AUTOSAR XML (schema 4-3-0)
standard types defined: UInt16, UInt32, UInt8, uint16, uint32, uint8
package /ARRoot/If
  11 x nv data interface:
    BsConst_BsConst_Illumination_ReservedByte
      nv-datas:
        data Value: type=Arr_u8_28
    BsConst_Compensation_Line_Shift_b
      nv-datas:
        data Value: type=UInt32
    BsConst_Compensation_Line_Slope_m
      nv-datas:
        data Value: type=UInt32
    BsConst_Derating_Backlight_Disable
      nv-datas:
        data Value: type=UInt8
    BsConst_Display_Illum_Max_Level
      nv-datas:
        data Value: type=UInt16
    BsConst_Lookup_Curve_HotSpot_Coef_X
      nv-datas:
        data Value: type=Arr_u16_7
    BsConst_Lookup_Curve_HotSpot_Coef_Y
      nv-datas:
        data Value: type=Arr_u16_7
    BsConst_PCB_Temperature_Sensor_Conv
      nv-datas:
        data Value: type=T_NV_Temperature_Conversion
    BsConst_PWM_boost_bypass_duty
      nv-datas:
        data Value: type=UInt8
    BsConst_Temp_Threshold_Hysteresis_Derating
      nv-datas:
        data Value: type=UInt8
    BsConst_Temperature_Sensor_Conv
      nv-datas:
        data Value: type=T_NV_Temperature_Conversion
package /E40_Platform_System_SystemPackage/Components
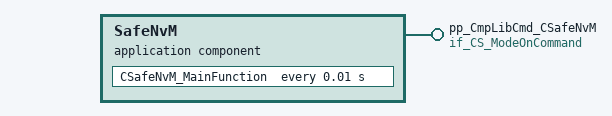
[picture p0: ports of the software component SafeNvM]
  application sw component type SafeNvM
    provide port pp_CmpLibCmd_CSafeNvM: server-com-spec{operation=Impl_OnCommand, queue-length=1}, provided-interface=if_CS_ModeOnCommand
    11 x provide/require port:
      BsConst_BsConst_Illumination_ReservedByte: nv-provide-com-spec=BsConst_BsConst_Illumination_ReservedByte/Value, nv-require-com-spec=BsConst_BsConst_Illumination_ReservedByte/Value, provided-required-interface=BsConst_BsConst_Illumination_ReservedByte
      BsConst_Compensation_Line_Shift_b: nv-provide-com-spec=BsConst_Compensation_Line_Shift_b/Value, nv-require-com-spec=BsConst_Compensation_Line_Shift_b/Value, provided-required-interface=BsConst_Compensation_Line_Shift_b
      BsConst_Compensation_Line_Slope_m: nv-provide-com-spec=BsConst_Compensation_Line_Slope_m/Value, nv-require-com-spec=BsConst_Compensation_Line_Slope_m/Value, provided-required-interface=BsConst_Compensation_Line_Slope_m
      BsConst_Derating_Backlight_Disable: nv-provide-com-spec=BsConst_Derating_Backlight_Disable/Value, nv-require-com-spec=BsConst_Derating_Backlight_Disable/Value, provided-required-interface=BsConst_Derating_Backlight_Disable
      BsConst_Display_Illum_Max_Level_Safe: nv-provide-com-spec=BsConst_Display_Illum_Max_Level/Value, nv-require-com-spec=BsConst_Display_Illum_Max_Level/Value, provided-required-interface=BsConst_Display_Illum_Max_Level
      BsConst_Lookup_Curve_HotSpot_Coef_X: nv-provide-com-spec=BsConst_Lookup_Curve_HotSpot_Coef_X/Value, nv-require-com-spec=BsConst_Lookup_Curve_HotSpot_Coef_X/Value, provided-required-interface=BsConst_Lookup_Curve_HotSpot_Coef_X
      BsConst_Lookup_Curve_HotSpot_Coef_Y: nv-provide-com-spec=BsConst_Lookup_Curve_HotSpot_Coef_Y/Value, nv-require-com-spec=BsConst_Lookup_Curve_HotSpot_Coef_Y/Value, provided-required-interface=BsConst_Lookup_Curve_HotSpot_Coef_Y
      BsConst_PCB_Temperature_Sensor_Conv: nv-provide-com-spec=BsConst_PCB_Temperature_Sensor_Conv/Value, nv-require-com-spec=BsConst_PCB_Temperature_Sensor_Conv/Value, provided-required-interface=BsConst_PCB_Temperature_Sensor_Conv
      BsConst_PWM_boost_bypass_duty: nv-provide-com-spec=BsConst_PWM_boost_bypass_duty/Value, nv-require-com-spec=BsConst_PWM_boost_bypass_duty/Value, provided-required-interface=BsConst_PWM_boost_bypass_duty
      BsConst_Temp_Threshold_Hysteresis_Derating: nv-provide-com-spec=BsConst_Temp_Threshold_Hysteresis_Derating/Value, nv-require-com-spec=BsConst_Temp_Threshold_Hysteresis_Derating/Value, provided-required-interface=BsConst_Temp_Threshold_Hysteresis_Derating
      BsConst_Temperature_Sensor_Conv: nv-provide-com-spec=BsConst_Temperature_Sensor_Conv/Value, nv-require-com-spec=BsConst_Temperature_Sensor_Conv/Value, provided-required-interface=BsConst_Temperature_Sensor_Conv
    behavior IB_SafeNvM: port-api-option{enable-take-address=false, error-handling=NO-TRANSFORMER-ERROR-HANDLING, indirect-api=false, port=pp_CmpLibCmd_CSafeNvM}
      operation invoked event OIE_pp_CmpLibCmd_CSafeNvM_CSafeNvM_Impl_OnCommandTrigByImpl_OnCommand: start-on-event=CSafeNvM_Impl_OnCommand, operation=pp_CmpLibCmd_CSafeNvM.Impl_OnCommand
      timing event TECSafeNvM_MainFunction: start-on-event=CSafeNvM_MainFunction, period=0.01
      11 x data received event:
        DRT_OnDre_Compensation_Line_Shift_b_BsConst_Compensation_Line_Shift_b_Value: start-on-event=OnDre_Compensation_Line_Shift_b, data=BsConst_Compensation_Line_Shift_b.Value
        DRT_OnDre_Compensation_Line_Slope_m_BsConst_Compensation_Line_Slope_m_Value: start-on-event=OnDre_Compensation_Line_Slope_m, data=BsConst_Compensation_Line_Slope_m.Value
        DRT_OnDre_Derating_Backlight_Disable_BsConst_Derating_Backlight_Disable_Value: start-on-event=OnDre_Derating_Backlight_Disable, data=BsConst_Derating_Backlight_Disable.Value
        DRT_OnDre_Display_Illum_Max_Level_Safe_BsConst_Display_Illum_Max_Level_Safe_Value: start-on-event=OnDre_Display_Illum_Max_Level_Safe, data=BsConst_Display_Illum_Max_Level_Safe.Value
        DRT_OnDre_Illumination_ReservedByte_BsConst_BsConst_Illumination_ReservedByte_Value: start-on-event=OnDre_Illumination_ReservedByte, data=BsConst_BsConst_Illumination_ReservedByte.Value
        DRT_OnDre_Lookup_Curve_HotSpot_Coef_X_BsConst_Lookup_Curve_HotSpot_Coef_X_Value: start-on-event=OnDre_Lookup_Curve_HotSpot_Coef_X, data=BsConst_Lookup_Curve_HotSpot_Coef_X.Value
        DRT_OnDre_Lookup_Curve_HotSpot_Coef_Y_BsConst_Lookup_Curve_HotSpot_Coef_Y_Value: start-on-event=OnDre_Lookup_Curve_HotSpot_Coef_Y, data=BsConst_Lookup_Curve_HotSpot_Coef_Y.Value
        DRT_OnDre_PCB_Temperature_Sensor_Conv_BsConst_PCB_Temperature_Sensor_Conv_Value: start-on-event=OnDre_PCB_Temperature_Sensor_Conv, data=BsConst_PCB_Temperature_Sensor_Conv.Value
        DRT_OnDre_PWM_boost_bypass_duty_BsConst_PWM_boost_bypass_duty_Value: start-on-event=OnDre_PWM_boost_bypass_duty, data=BsConst_PWM_boost_bypass_duty.Value
        DRT_OnDre_Temp_Threshold_Hysteresis_Derating_BsConst_Temp_Threshold_Hysteresis_Derating_Value: start-on-event=OnDre_Temp_Threshold_Hysteresis_Derating, data=BsConst_Temp_Threshold_Hysteresis_Derating.Value
        DRT_OnDre_Temperature_Sensor_Conv_BsConst_Temperature_Sensor_Conv_Value: start-on-event=OnDre_Temperature_Sensor_Conv, data=BsConst_Temperature_Sensor_Conv.Value
      13 x runnable, all with can-be-invoked-concurrently=true:
        CSafeNvM_Impl_OnCommand
        CSafeNvM_MainFunction
        OnDre_Compensation_Line_Shift_b
        OnDre_Compensation_Line_Slope_m
        OnDre_Derating_Backlight_Disable
        OnDre_Display_Illum_Max_Level_Safe
        OnDre_Illumination_ReservedByte
        OnDre_Lookup_Curve_HotSpot_Coef_X
        OnDre_Lookup_Curve_HotSpot_Coef_Y
        OnDre_PCB_Temperature_Sensor_Conv
        OnDre_PWM_boost_bypass_duty
        OnDre_Temp_Threshold_Hysteresis_Derating
        OnDre_Temperature_Sensor_Conv
  swc implementation IMPL_SafeNvM: behavior=IB_SafeNvM
    code-descriptors:
      code Default: artifact-descriptors=autosar-engineering-object={short-label=Default, category=SWSRC}
package /E40_Platform_System_SystemPackage/Types
  client server interface if_CS_ModeOnCommand
    operation Impl_OnCommand: possible-error=E_NOT_OK
      arg cmdP: type=ECmpCmd, direction=IN, server-argument-impl-policy=USE-ARGUMENT-TYPE
    error E_NOT_OK: error-code=1
  4 x impl type:
    Arr_u16_7: category=ARRAY
      element ArrayElement: category=VALUE, array-size=7, array-size-semantics=FIXED-SIZE, base-type=uint16
    Arr_u8_28: category=ARRAY
      element ArrayElement: category=VALUE, array-size=28, array-size-semantics=FIXED-SIZE, base-type=uint8
    ECmpCmd: category=VALUE, base-type=uint8, compu {0=eCmpCmd_Init, 1=eCmpCmd_DeInit, 2=eCmpCmd_Activate, 3=eCmpCmd_DeActivate}, range raw 0..3
    T_NV_Temperature_Conversion: category=ARRAY
      element ArrayElement: category=VALUE, array-size=2, array-size-semantics=FIXED-SIZE, base-type=uint32
package /E40_Platform_System_SystemPackage/Types/DataConstrs
  range UInt16_DataConstraint: raw 0..65535
  range UInt32_DataConstraint: raw 0..4294967295
  range UInt8_DataConstraint: raw 0..255
